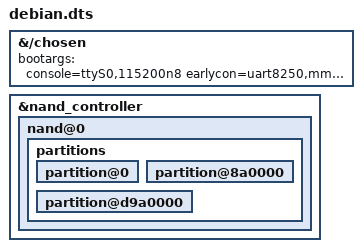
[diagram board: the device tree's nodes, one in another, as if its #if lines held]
// SPDX-License-Identifier: GPL-2.0
/*
 * m1-debian: the full kernel booting the Debian root on the SD card with
 * init.mainline (docs/kernel/debian_root_boot.md, step D2)
 */
#include "../full.dts"

&{/chosen} {
	bootargs = "console=ttyS0,115200n8 earlycon=uart8250,mmio32,0xf8060000 root=/dev/mmcblk0p1 rootwait ro rdinit=/nonexistent init=/etc/dp200/init.mainline panic=10";
};

#ifdef DP200_NANDW
/*
 * NANDW=1 test images only: mtd0 "kernel", mtd3 "boot-logo" and mtd6
 * "filesystem" writable (step 3, back to stock). The driver's write window
 * (patch 0010, empty by default) still decides block by block, and never
 * allows U-Boot (mtd0's first 2 blocks), mtd1, mtd2, mtd4 or mtd5.
 */
&nand_controller {
	nand@0 {
		partitions {
			partition@0 {
				/delete-property/ read-only;
			};
			partition@8a0000 {
				/delete-property/ read-only;
			};
			partition@d9a0000 {
				/delete-property/ read-only;
			};
		};
	};
};
#endif
